# R7KA8P1AD register map
Vendor: Renesas Electronics Corporation; Series: RA8; File version: 1.10.02
CPU: CM85 r0p2, little endian, MPU, FPU, VTOR, 4 interrupt priority bits, 96 interrupts
Registers are 32-bit, read-write, reset 0x0 unless marked. A register's access mark holds for its fields unless they carry their own. Offsets are from the block's base; [hi:lo] are bit positions; {n}, {i} and the like mark numbered series; 'fields as' and 'values as' point back to an identical list.

## MSTP_NS — Module Stop Control
Base 0x50203000
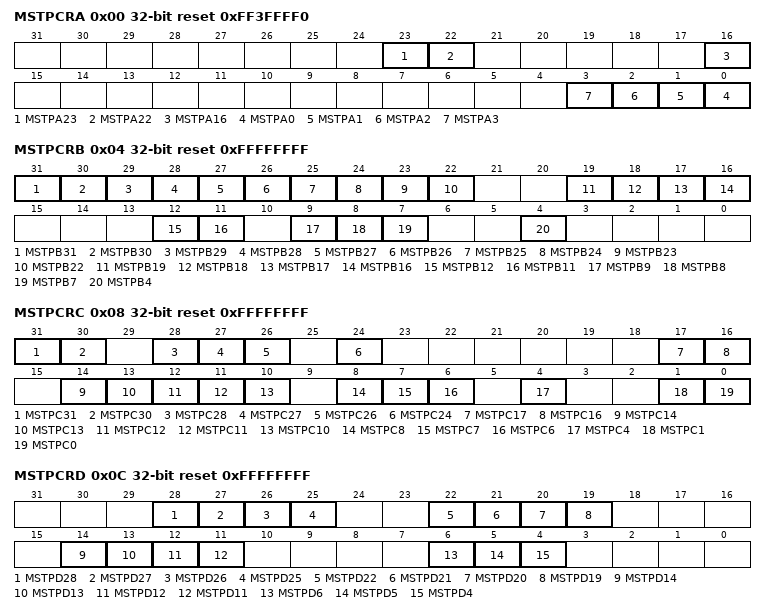
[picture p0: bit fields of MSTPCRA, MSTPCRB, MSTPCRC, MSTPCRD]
0x00 MSTPCRA reset 0xFF3FFFF0 — Module Stop Control Register A
  [all] fields
    0=Cancel the module-stop state; 1=Enter the module-stop state
  [23] MSTPA23 — DMA Controller 1 and Data Transfer Controller 1 Module Stop
  [22] MSTPA22 — DMA Controller 0 and Data Transfer Controller 0 Module Stop
  [16] MSTPA16 — NPU Module Stop
  [n] MSTPA{n} (n=0..3) — SRAM{n} Module Stop
0x04 MSTPCRB reset 0xFFFFFFFF — Module Stop Control Register B
  [all] fields
    values as the fields of MSTPCRA
  [31] MSTPB31 — Serial Communication Interface 0 Module Stop
  [30] MSTPB30 — Serial Communication Interface 1 Module Stop
  [29] MSTPB29 — Serial Communication Interface 2 Module Stop
  [28] MSTPB28 — Serial Communication Interface 3 Module Stop
  [27] MSTPB27 — Serial Communication Interface 4 Module Stop
  [26] MSTPB26 — Serial Communication Interface 5 Module Stop
  [25] MSTPB25 — Serial Communication Interface 6 Module Stop
  [24] MSTPB24 — Serial Communication Interface 7 Module Stop
  [23] MSTPB23 — Serial Communication Interface 8 Module Stop
  [22] MSTPB22 — Serial Communication Interface 9 Module Stop
  [19] MSTPB19 — Serial Peripheral Interface 0 Module Stop
  [18] MSTPB18 — Serial Peripheral Interface 1 Module Stop
  [17] MSTPB17 — Octal Serial Peripheral Interface 1 and Decryption On The Fly 1 Module Stop
  [16] MSTPB16 — Octal Serial Peripheral Interface 0 and Decryption On The Fly 0 Module Stop
  [12] MSTPB12 — Universal Serial Bus 2.0 HS Interface Module Stop
  [11] MSTPB11 — Universal Serial Bus 2.0 FS Interface 0 Module Stop
  [9] MSTPB9 — IIC Bus Interface 0 Module Stop
  [8] MSTPB8 — IIC Bus Interface 1 Module Stop
  [7] MSTPB7 — IIC Bus Interface 2 Module Stop
  [4] MSTPB4 — I3C Bus Interface Module Stop
0x08 MSTPCRC reset 0xFFFFFFFF — Module Stop Control Register C
  [all] fields
    values as the fields of MSTPCRA
  [31] MSTPC31 — Renesas Secure IP Module Stop
  [30] MSTPC30 — Layer 3 Ethernet Switch Module Module Stop
  [28] MSTPC28 — Ether-PHY clock Module Stop
  [27] MSTPC27 — Controller Area Network with Flexible Data-Rate 0 Module Stop
  [26] MSTPC26 — Controller Area Network with Flexible Data-Rate 1 Module Stop
  [24] MSTPC24 — Pulse Density Modulation Interface Module Stop
  [17] MSTPC17 — MIPI Camera Serial Interface Module Stop
  [16] MSTPC16 — Capture Engine Unit Module Stop
  [14] MSTPC14 — Event Link Controller Module Stop
  [13] MSTPC13 — Data Operation Circuit Module Stop
  [12] MSTPC12 — Secure Digital Host IF 0 Module Stop
  [11] MSTPC11 — Secure Digital Host IF 1 Module Stop
  [10] MSTPC10 — MIPI Display Serial Interface Module Stop
  [8] MSTPC8 — Serial Sound Interface Enhanced 0 Module Stop
  [7] MSTPC7 — Serial Sound Interface Enhanced 1 Module Stop
  [6] MSTPC6 — 2D Drawing Engine Module Stop
  [4] MSTPC4 — Graphics LCD Controller Module Stop
  [1] MSTPC1 — Cyclic Redundancy Check Calculator Module Stop
  [0] MSTPC0 — Clock Frequency Accuracy Measurement Circuit Module Stop
0x0C MSTPCRD reset 0xFFFFFFFF — Module Stop Control Register D
  [all] fields
    values as the fields of MSTPCRA
  [28] MSTPD28 — High-Speed Analog Comparator 0 Module Stop
  [27] MSTPD27 — High-Speed Analog Comparator 1 Module Stop
  [26] MSTPD26 — High-Speed Analog Comparator 2 Module Stop
  [25] MSTPD25 — High-Speed Analog Comparator 3 Module Stop
  [22] MSTPD22 — Temperature Sensor Module Stop
  [21] MSTPD21 — 16-Bit A/D Converter Module Stop
  [20] MSTPD20 — 12-bit D/A Converter 0 Module Stop
  [19] MSTPD19 — 12-bit D/A Converter 1 Module Stop
  [14] MSTPD14 — Port Output Enable for GPT Group A Module Stop
  [13] MSTPD13 — Port Output Enable for GPT Group B Module Stop
  [12] MSTPD12 — Port Output Enable for GPT Group C Module Stop
  [11] MSTPD11 — Port Output Enable for GPT Group D Module Stop
  [6] MSTPD6 — PWM Delay Generation Circuit Module Stop
  [5] MSTPD5 — Low power Asynchronous General Purpose Timer 0 Module Stop
  [4] MSTPD4 — Low power Asynchronous General Purpose Timer 1 Module Stop
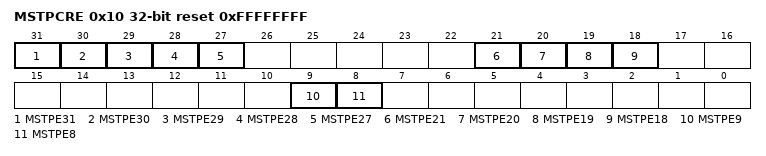
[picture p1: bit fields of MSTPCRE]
0x10 MSTPCRE reset 0xFFFFFFFF — Module Stop Control Register E
  [all] fields
    values as the fields of MSTPCRA
  [31] MSTPE31 — General PWM Timer 0 Module Stop
  [30] MSTPE30 — General PWM Timer 1 Module Stop
  [29] MSTPE29 — General PWM Timer 2 Module Stop
  [28] MSTPE28 — General PWM Timer 3 Module Stop
  [27] MSTPE27 — General PWM Timer 4-9 Module Stop
  [21] MSTPE21 — General PWM Timer 10 Module Stop
  [20] MSTPE20 — General PWM Timer 11 Module Stop
  [19] MSTPE19 — General PWM Timer 12 Module Stop
  [18] MSTPE18 — General PWM Timer 13 Module Stop
  [9] MSTPE9 — Ultra-Low Power Timer 0 Module Stop
  [8] MSTPE8 — Ultra-Low Power Timer 1 Module Stop
